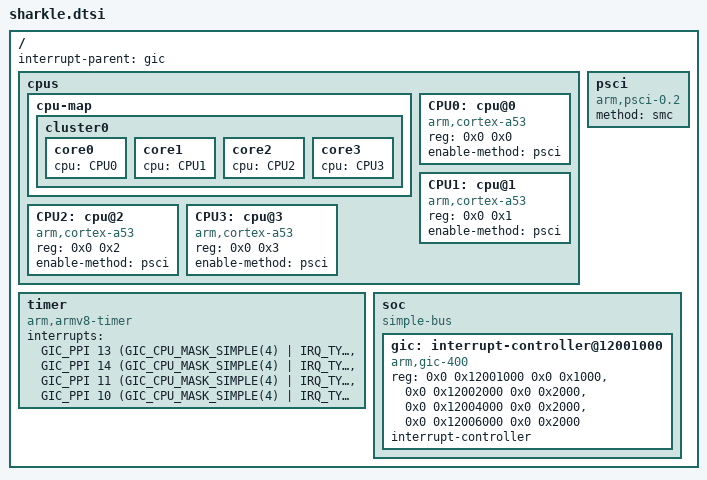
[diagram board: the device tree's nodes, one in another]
// SPDX-License-Identifier: GPL-2.0-only
/*
 * Unisoc Sharkle platform DTS file
 *
 * Copyright (C) 2026, Unisoc Inc.
 */
#include <dt-bindings/interrupt-controller/arm-gic.h>

/ {
	#address-cells = <2>;
	#size-cells = <2>;
	interrupt-parent = <&gic>;

	cpus {
		#address-cells = <2>;
		#size-cells = <0>;

		cpu-map {
			cluster0 {
				core0 { cpu = <&CPU0>; };
				core1 { cpu = <&CPU1>; };
				core2 { cpu = <&CPU2>; };
				core3 { cpu = <&CPU3>; };
			};
		};

		CPU0: cpu@0 {
			device_type = "cpu";
			compatible = "arm,cortex-a53", "arm,armv8";
			reg = <0x0 0x0>;
			enable-method = "psci";
		};

		CPU1: cpu@1 {
			device_type = "cpu";
			compatible = "arm,cortex-a53", "arm,armv8";
			reg = <0x0 0x1>;
			enable-method = "psci";
		};

		CPU2: cpu@2 {
			device_type = "cpu";
			compatible = "arm,cortex-a53", "arm,armv8";
			reg = <0x0 0x2>;
			enable-method = "psci";
		};

		CPU3: cpu@3 {
			device_type = "cpu";
			compatible = "arm,cortex-a53", "arm,armv8";
			reg = <0x0 0x3>;
			enable-method = "psci";
		};
	};

	psci {
		compatible = "arm,psci-0.2";
		method = "smc";
	};

	timer {
		compatible = "arm,armv8-timer";
		interrupts = <GIC_PPI 13 (GIC_CPU_MASK_SIMPLE(4) | IRQ_TYPE_LEVEL_LOW)>,
			     <GIC_PPI 14 (GIC_CPU_MASK_SIMPLE(4) | IRQ_TYPE_LEVEL_LOW)>,
			     <GIC_PPI 11 (GIC_CPU_MASK_SIMPLE(4) | IRQ_TYPE_LEVEL_LOW)>,
			     <GIC_PPI 10 (GIC_CPU_MASK_SIMPLE(4) | IRQ_TYPE_LEVEL_LOW)>;
	};

	soc: soc {
		compatible = "simple-bus";
		#address-cells = <2>;
		#size-cells = <2>;
		ranges;

		gic: interrupt-controller@12001000 {
			compatible = "arm,gic-400";
			reg = <0x0 0x12001000 0x0 0x1000>,
			      <0x0 0x12002000 0x0 0x2000>,
			      <0x0 0x12004000 0x0 0x2000>,
			      <0x0 0x12006000 0x0 0x2000>;
			#interrupt-cells = <3>;
			interrupt-controller;
		};
	};
};
